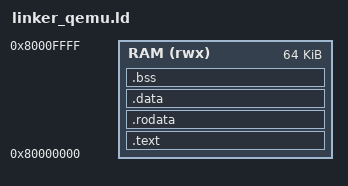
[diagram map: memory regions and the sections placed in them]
MEMORY {
    RAM (rwx) : ORIGIN = 0x80000000, LENGTH = 64K
}

SECTIONS {
    .text : { *(.init) *(.text*) } > RAM
    .rodata : { *(.rodata*) } > RAM
    .data : { *(.data*) } > RAM
    .bss : { *(.bss*) *(COMMON) } > RAM

    _stack_top = ORIGIN(RAM) + LENGTH(RAM);
}
